# STC32G144K246 register map
Vendor: STC; File version: 2.0
Registers are 8-bit, read-write, no defined reset value unless marked. A register's access mark holds for its fields unless they carry their own. Offsets are from the block's base; [hi:lo] are bit positions.

## I2C1 — I2C1 主从配置、应答和中断状态
Base 0x007EFD85
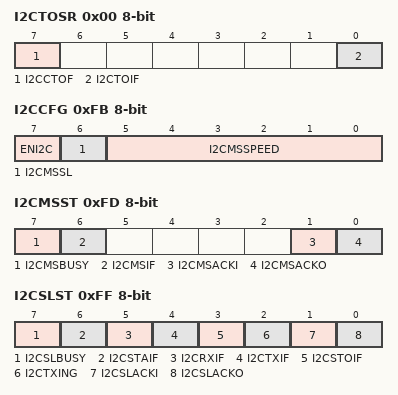
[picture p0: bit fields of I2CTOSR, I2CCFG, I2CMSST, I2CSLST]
0x00 I2CTOSR ro — I2C从机超时状态寄存器
  [7] I2CCTOF — 尚未自动匹配到此字段的独立说明；请查看下方章节说明。
  [0] I2CTOIF — I2C1 超时中断请求标志位。标志位需要软件向I2CCTOIF 位写“1”清零
0xFB I2CCFG — 2IC配置寄存器
  [7] ENI2C — I2C 功能使能控制位
    0=禁止I2C 功能; 1=允许I2C 功能
  [6] I2CMSSL — I2C 工作模式选择位
    0=从机模式; 1=主机模式
  [5:0] I2CMSSPEED — I2C 总线速度（等待时钟数）控制 I2C 总线速度＝SYSCLK / 2 / (I2CMSSPEED * 2 + 4) （I2C 最快速度为SYSCLK/8）
0xFD I2CMSST ro — 2IC主机状态寄存器
  [7] I2CMSBUSY — 主机模式时I2C 控制器状态位（只读位）
    0=控制器处于空闲状态; 1=控制器处于忙碌状态
  [6] I2CMSIF — 主机模式的中断请求位（中断标志位）。当处于主机模式的I2C控制器执行完成寄存器I2CMSCR 中MSCMD 命令后产生中断信号，硬件自动将此位1，向CPU 发请求中断，响应中断后MSIF 位必 须用软件清零。
  [1] I2CMSACKI — 主机模式时，发送“0011”命令到I2CMSCR 的I2CMSCMD 位后所接收到的ACK 数据。 （只读位）
  [0] I2CMSACKO — 主机模式时，准备将要发送出去的 ACK 信号。当发送“0101”命令到 I2CMSCR 的 I2CMSCMD 位后，控制器会自动读取此位的数据当作ACK 发送到SDA。
0xFF I2CSLST ro — 2IC从机状态寄存器
  [7] I2CSLBUSY — 从机模式时I2C 控制器状态位（只读位）
    0=控制器处于空闲状态; 1=控制器处于忙碌状态
  [6] I2CSTAIF — 从机模式时接收到START 信号后的中断请求位。从机模式的I2C 控制器接收到START 信号 后，硬件会自动将此位置1，并向CPU 发请求中断，响应中断后STAIF 位必须用软件清零。STAIF 被置1 的时间点如下图所示：
  [5] I2CRXIF — 尚未自动匹配到此字段的独立说明；请查看下方章节说明。
  [4] I2CTXIF — 从机模式时发送完成1 字节的数据后的中断请求位。从机模式的I2C 控制器发送完成1 字节 的数据并成功接收到1 位ACK 信号后，在第9 个时钟的下降沿时硬件会自动将此位置1，并向CPU
  [3] I2CSTOIF — 从机模式时接收到STOP 信号后的中断请求位。从机模式的I2C 控制器接收到STOP 信号后， 硬件会自动将此位置1，并向CPU 发请求中断，响应中断后I2CSTOIF 位必须用软件清零。I2CSTOIF 被置1 的时间点如下图所示：
  [2] I2CTXING — 尚未自动匹配到此字段的独立说明；请查看下方章节说明。
  [1] I2CSLACKI — 尚未自动匹配到此字段的独立说明；请查看下方章节说明。
  [0] I2CSLACKO — 从机模式时，准备将要发送出去的ACK 信号。
0x104 I2CPSCR — 2IC时钟预分配寄存器
  [7:0] I2CMSSPEED — I2C 总线速度（等待时钟数）控制 I2C 总线速度＝SYSCLK / 2 / (I2CMSSPEED * 2 + 4) （I2C 最快速度为SYSCLK/8）

## I2C2 — I2C2 主从配置、应答和中断状态
Base 0x007EF860
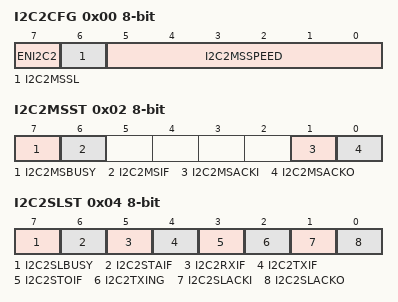
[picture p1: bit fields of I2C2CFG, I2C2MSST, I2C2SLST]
0x00 I2C2CFG — 2IC配置寄存器
  [7] ENI2C2 — I2C2 功能使能控制位
    0=禁止I2C2 功能; 1=允许I2C2 功能
  [6] I2C2MSSL — I2C2 工作模式选择位
    0=从机模式; 1=主机模式
  [5:0] I2C2MSSPEED — I2C2 总线速度（等待时钟数）控制 I2C2 总线速度＝SYSCLK / 2 / (I2C2MSSPEED * 2 + 4) （I2C2 最快速度为SYSCLK/8）
0x02 I2C2MSST ro — 2IC主机状态寄存器
  [7] I2C2MSBUSY — 主机模式时I2C2 控制器状态位（只读位）
    0=控制器处于空闲状态; 1=控制器处于忙碌状态
  [6] I2C2MSIF — 主机模式的中断请求位（中断标志位）。需要软件清零。
  [1] I2C2MSACKI — 主机模式时，发送“0011”命令到I2C2MSCR 的I2C2MSCMD 位后所接收到的ACK 数 据。（只读位）
  [0] I2C2MSACKO — 主机模式时，准备将要发送出去的 ACK 信号。当发送“0101”命令到 I2C2MSCR 的 I2C2MSCMD 位后，控制器会自动读取此位的数据当作ACK 发送到SDA2。
0x04 I2C2SLST ro — 2IC从机状态寄存器
  [7] I2C2SLBUSY — 从机模式时I2C2 控制器状态位（只读位）
    0=控制器处于空闲状态; 1=控制器处于忙碌状态
  [6] I2C2STAIF — IC从机接收START事件中断请求标志。需要软件清零。 2
  [5] I2C2RXIF — IC从机接收数据完成事件中断请求标志。需要软件清零。 2
  [4] I2C2TXIF — IC从机发送数据完成事件中断请求标志。需要软件清零。 2
  [3] I2C2STOIF — IC从机接收STOP事件中断请求标志。需要软件清零。
  [2] I2C2TXING — 尚未自动匹配到此字段的独立说明；请查看下方章节说明。
  [1] I2C2SLACKI — 尚未自动匹配到此字段的独立说明；请查看下方章节说明。
  [0] I2C2SLACKO — 从机模式时，准备将要发送出去的ACK 信号。
0x09 I2C2PSCR — 2IC时钟预分配寄存器
  [7:0] I2C2MSSPEED — I2C2 总线速度（等待时钟数）控制 I2C2 总线速度＝SYSCLK / 2 / (I2C2MSSPEED * 2 + 4) （I2C2 最快速度为SYSCLK/8）
0x0D I2C2TOSR ro — 2IC2从机超时状态寄存器
  [0] I2C2TOIF — I2C2 超时中断请求标志位。标志位需要软件向I2C2CTOIF 位写“1”清零

## HSPWMA — 高速 PWM A 配置；不访问间接窗口
Base 0x007EFBF0
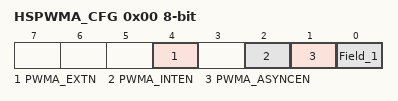
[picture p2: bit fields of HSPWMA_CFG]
0x00 HSPWMA_CFG ro — 高速PWMA配置寄存器
  [4] PWMA_EXTN — PWMA 间接寻址的基地址选择
    0=间接寻址的基地址，BASE[15:7] = 0x1fd，间接寻址范围为FE80H～FEFFH; 1=间接寻址的基地址，BASE[15:7] = 0x1f2，间接寻址范围为F900H～F97FH
  [2] PWMA_INTEN — 异步模式中断使能位（n=A/B/C/D/E/F）
    0=关闭异步模式下的PWMn 中断。; 1=使能异步模式下的PWMn 中断。
  [1] PWMA_ASYNCEN — 异步控制模式使能位（n=A/B/C/D/E/F）
    0=关闭异步控制。; 1=使能异步控制模式。
  [0] Field_1 — 尚未自动匹配到此字段的独立说明；请查看下方章节说明。

## HSPWMB — 高速 PWM B 配置；不访问间接窗口
Base 0x007EFBF4
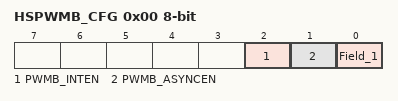
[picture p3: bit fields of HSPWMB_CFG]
0x00 HSPWMB_CFG ro — 高速PWMB配置寄存器
  [2] PWMB_INTEN — 异步模式中断使能位（n=A/B/C/D/E/F）
    0=关闭异步模式下的PWMn 中断。; 1=使能异步模式下的PWMn 中断。
  [1] PWMB_ASYNCEN — 异步控制模式使能位（n=A/B/C/D/E/F）
    0=关闭异步控制。; 1=使能异步控制模式。
  [0] Field_1 — 尚未自动匹配到此字段的独立说明；请查看下方章节说明。

## HSPWMC — 高速 PWM C 配置；不访问间接窗口
Base 0x007EF970
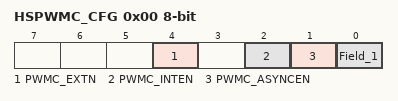
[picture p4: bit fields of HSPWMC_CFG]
0x00 HSPWMC_CFG ro — 高速PWMC配置寄存器
  [4] PWMC_EXTN — PWMC 间接寻址的基地址选择
    0=间接寻址的基地址，BASE[15:7] = 0x1f1，间接寻址范围为F880H～F8FFH; 1=间接寻址的基地址，BASE[15:7] = 0x1f2，间接寻址范围为F900H～F97FH
  [2] PWMC_INTEN — 异步模式中断使能位（n=A/B/C/D/E/F）
    0=关闭异步模式下的PWMn 中断。; 1=使能异步模式下的PWMn 中断。
  [1] PWMC_ASYNCEN — 异步控制模式使能位（n=A/B/C/D/E/F）
    0=关闭异步控制。; 1=使能异步控制模式。
  [0] Field_1 — 尚未自动匹配到此字段的独立说明；请查看下方章节说明。
